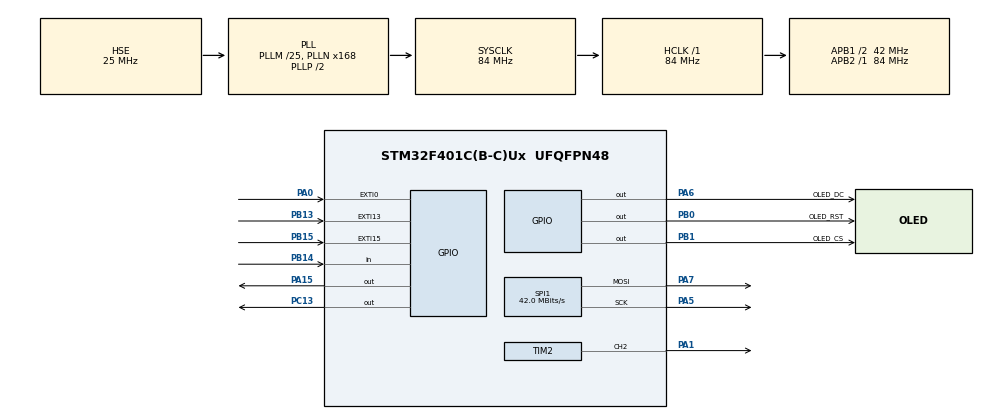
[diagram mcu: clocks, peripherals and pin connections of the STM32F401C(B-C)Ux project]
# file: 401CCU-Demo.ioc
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FREERTOS.Mutexes01=myMutex01,Dynamic,NULL
FREERTOS.Tasks01=MainTask,0,128,StartMainTask,Default,NULL,Dynamic,NULL,NULL
FREERTOS.configENABLE_FPU=1
FREERTOS.configUSE_COUNTING_SEMAPHORES=1
FREERTOS.configUSE_RECURSIVE_MUTEXES=1
Mcu.Family=STM32F4
Mcu.Name=STM32F401C(B-C)Ux
Mcu.Package=UFQFPN48
NVIC.EXTI0_IRQn=true\:5\:0\:false\:false\:true\:true\:true\:true
NVIC.EXTI15_10_IRQn=true\:5\:0\:false\:false\:true\:true\:true\:true
NVIC.PriorityGroup=NVIC_PRIORITYGROUP_4
NVIC.TIM1_UP_TIM10_IRQn=true\:15\:0\:false\:false\:true\:false\:false\:true
NVIC.TIM2_IRQn=true\:5\:0\:false\:false\:true\:true\:true\:true
NVIC.TimeBase=TIM1_UP_TIM10_IRQn
NVIC.TimeBaseIP=TIM1
PA0-WKUP.GPIO_PuPd=GPIO_PULLUP
PA0-WKUP.Signal=GPXTI0
PA1.Signal=S_TIM2_CH2
PA13.Mode=Serial_Wire
PA13.Signal=SYS_JTMS-SWDIO
PA14.Mode=Serial_Wire
PA14.Signal=SYS_JTCK-SWCLK
PA15.Signal=GPIO_Output
PA5.Mode=TX_Only_Simplex_Unidirect_Master
PA5.Signal=SPI1_SCK
PA6.GPIO_Label=OLED_DC
PA6.GPIO_Speed=GPIO_SPEED_FREQ_VERY_HIGH
PA6.Signal=GPIO_Output
PA7.Mode=TX_Only_Simplex_Unidirect_Master
PA7.Signal=SPI1_MOSI
PB0.GPIO_Label=OLED_RST
PB0.GPIO_Speed=GPIO_SPEED_FREQ_VERY_HIGH
PB0.PinState=GPIO_PIN_SET
PB0.Signal=GPIO_Output
PB1.GPIO_Label=OLED_CS
PB1.GPIO_Speed=GPIO_SPEED_FREQ_VERY_HIGH
PB1.Signal=GPIO_Output
PB13.GPIO_ModeDefaultEXTI=GPIO_MODE_IT_RISING
PB13.GPIO_PuPd=GPIO_PULLDOWN
PB13.Signal=GPXTI13
PB14.Signal=GPIO_Input
PB15.GPIO_ModeDefaultEXTI=GPIO_MODE_IT_FALLING
PB15.GPIO_PuPd=GPIO_PULLDOWN
PB15.Signal=GPXTI15
PC13-ANTI_TAMP.Signal=GPIO_Output
PC14-OSC32_IN.Mode=LSE-External-Oscillator
PC14-OSC32_IN.Signal=RCC_OSC32_IN
PC15-OSC32_OUT.Mode=LSE-External-Oscillator
PC15-OSC32_OUT.Signal=RCC_OSC32_OUT
PH0\ -\ OSC_IN.Mode=HSE-External-Oscillator
PH0\ -\ OSC_IN.Signal=RCC_OSC_IN
PH1\ -\ OSC_OUT.Mode=HSE-External-Oscillator
PH1\ -\ OSC_OUT.Signal=RCC_OSC_OUT
ProjectManager.HeapSize=0x200
ProjectManager.StackSize=0x400
ProjectManager.TargetToolchain=Makefile
RCC.48MHZClocksFreq_Value=42000000
RCC.AHBFreq_Value=84000000
RCC.APB1CLKDivider=RCC_HCLK_DIV2
RCC.APB1Freq_Value=42000000
RCC.APB1TimFreq_Value=84000000
RCC.APB2Freq_Value=84000000
RCC.APB2TimFreq_Value=84000000
RCC.CortexFreq_Value=84000000
RCC.HCLKFreq_Value=84000000
RCC.HSE_VALUE=25000000
RCC.HSI_VALUE=16000000
RCC.PLLM=25
RCC.PLLN=168
RCC.PLLSourceVirtual=RCC_PLLSOURCE_HSE
RCC.RCC_RTC_Clock_Source=RCC_RTCCLKSOURCE_LSE
RCC.SYSCLKFreq_VALUE=84000000
RCC.SYSCLKSource=RCC_SYSCLKSOURCE_PLLCLK
RCC.VCOOutputFreq_Value=168000000
SH.S_TIM2_CH2.0=TIM2_CH2,PWM Generation2 CH2
SPI1.CalculateBaudRate=42.0 MBits/s
SPI1.Direction=SPI_DIRECTION_2LINES
SPI1.Mode=SPI_MODE_MASTER
SPI1.VirtualType=VM_MASTER
TIM2.AutoReloadPreload=TIM_AUTORELOAD_PRELOAD_ENABLE
TIM2.Channel-PWM\ Generation2\ CH2=TIM_CHANNEL_2
TIM2.Period=999
TIM2.Prescaler=83
TIM2.TIM_MasterSlaveMode=TIM_MASTERSLAVEMODE_DISABLE
VP_FREERTOS_VS_CMSIS_V1.Mode=CMSIS_V1
VP_RTC_VS_RTC_Activate.Mode=RTC_Enabled
VP_SYS_VS_tim1.Mode=TIM1
VP_TIM2_VS_ClockSourceINT.Mode=Internal
board=custom

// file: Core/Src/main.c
/* USER CODE BEGIN Header */
/**
  ******************************************************************************
  * @file           : main.c
  * @brief          : Main program body
  ******************************************************************************
  * @attention
  *
  * <h2><center>&copy; Copyright (c) 2021 STMicroelectronics.
  * All rights reserved.</center></h2>
  *
  * This software component is licensed by ST under BSD 3-Clause license,
  * the "License"; You may not use this file except in compliance with the
  * License. You may obtain a copy of the License at:
  *                        opensource.org/licenses/BSD-3-Clause
  *
  ******************************************************************************
  */
/* USER CODE END Header */
#include "main.h"
#include "cmsis_os.h"

/* USER CODE BEGIN Includes */
#include "mysetp.h"
/* USER CODE END Includes */

RTC_HandleTypeDef hrtc;

SPI_HandleTypeDef hspi1;

TIM_HandleTypeDef htim2;

osThreadId MainTaskHandle;
osMutexId myMutex01Handle;

void SystemClock_Config(void);
static void MX_GPIO_Init(void);
static void MX_SPI1_Init(void);
static void MX_TIM2_Init(void);
static void MX_RTC_Init(void);
void StartMainTask(void const * argument);

int main(void)
{

  /* MCU Configuration--------------------------------------------------------*/

  /* Reset of all peripherals, Initializes the Flash interface and the Systick. */
  HAL_Init();

  /* Configure the system clock */
  SystemClock_Config();

  /* Initialize all configured peripherals */
  MX_GPIO_Init();
  MX_SPI1_Init();
  MX_TIM2_Init();
  MX_RTC_Init();
  /* USER CODE BEGIN 2 */
  HAL_TIM_Base_Start(&htim2);
  HAL_TIM_PWM_Start(&htim2,TIM_CHANNEL_2);
  /* USER CODE END 2 */

  /* Create the mutex(es) */
  /* definition and creation of myMutex01 */
  osMutexDef(myMutex01);
  myMutex01Handle = osMutexCreate(osMutex(myMutex01));

  /* Create the thread(s) */
  /* definition and creation of MainTask */
  osThreadDef(MainTask, StartMainTask, osPriorityNormal, 0, 128);
  MainTaskHandle = osThreadCreate(osThread(MainTask), NULL);

  /* Start scheduler */
  osKernelStart();

  /* We should never get here as control is now taken by the scheduler */
  /* Infinite loop */
  while (1)
  {

  }
}

void SystemClock_Config(void)
{
  RCC_OscInitTypeDef RCC_OscInitStruct = {0};
  RCC_ClkInitTypeDef RCC_ClkInitStruct = {0};

  /** Configure the main internal regulator output voltage
  */
  __HAL_RCC_PWR_CLK_ENABLE();
  __HAL_PWR_VOLTAGESCALING_CONFIG(PWR_REGULATOR_VOLTAGE_SCALE2);
  /** Initializes the RCC Oscillators according to the specified parameters
  * in the RCC_OscInitTypeDef structure.
  */
  RCC_OscInitStruct.OscillatorType = RCC_OSCILLATORTYPE_HSE|RCC_OSCILLATORTYPE_LSE;
  RCC_OscInitStruct.HSEState = RCC_HSE_ON;
  RCC_OscInitStruct.LSEState = RCC_LSE_ON;
  RCC_OscInitStruct.PLL.PLLState = RCC_PLL_ON;
  RCC_OscInitStruct.PLL.PLLSource = RCC_PLLSOURCE_HSE;
  RCC_OscInitStruct.PLL.PLLM = 25;
  RCC_OscInitStruct.PLL.PLLN = 168;
  RCC_OscInitStruct.PLL.PLLP = RCC_PLLP_DIV2;
  RCC_OscInitStruct.PLL.PLLQ = 4;
  if (HAL_RCC_OscConfig(&RCC_OscInitStruct) != HAL_OK)
  {
    Error_Handler();
  }
  /** Initializes the CPU, AHB and APB buses clocks
  */
  RCC_ClkInitStruct.ClockType = RCC_CLOCKTYPE_HCLK|RCC_CLOCKTYPE_SYSCLK
                              |RCC_CLOCKTYPE_PCLK1|RCC_CLOCKTYPE_PCLK2;
  RCC_ClkInitStruct.SYSCLKSource = RCC_SYSCLKSOURCE_PLLCLK;
  RCC_ClkInitStruct.AHBCLKDivider = RCC_SYSCLK_DIV1;
  RCC_ClkInitStruct.APB1CLKDivider = RCC_HCLK_DIV2;
  RCC_ClkInitStruct.APB2CLKDivider = RCC_HCLK_DIV1;

  if (HAL_RCC_ClockConfig(&RCC_ClkInitStruct, FLASH_LATENCY_2) != HAL_OK)
  {
    Error_Handler();
  }
}

static void MX_RTC_Init(void)
{

  /** Initialize RTC Only
  */
  hrtc.Instance = RTC;
  hrtc.Init.HourFormat = RTC_HOURFORMAT_24;
  hrtc.Init.AsynchPrediv = 127;
  hrtc.Init.SynchPrediv = 255;
  hrtc.Init.OutPut = RTC_OUTPUT_DISABLE;
  hrtc.Init.OutPutPolarity = RTC_OUTPUT_POLARITY_HIGH;
  hrtc.Init.OutPutType = RTC_OUTPUT_TYPE_OPENDRAIN;
  if (HAL_RTC_Init(&hrtc) != HAL_OK)
  {
    Error_Handler();
  }

}

static void MX_SPI1_Init(void)
{

  /* SPI1 parameter configuration*/
  hspi1.Instance = SPI1;
  hspi1.Init.Mode = SPI_MODE_MASTER;
  hspi1.Init.Direction = SPI_DIRECTION_2LINES;
  hspi1.Init.DataSize = SPI_DATASIZE_8BIT;
  hspi1.Init.CLKPolarity = SPI_POLARITY_LOW;
  hspi1.Init.CLKPhase = SPI_PHASE_1EDGE;
  hspi1.Init.NSS = SPI_NSS_SOFT;
  hspi1.Init.BaudRatePrescaler = SPI_BAUDRATEPRESCALER_2;
  hspi1.Init.FirstBit = SPI_FIRSTBIT_MSB;
  hspi1.Init.TIMode = SPI_TIMODE_DISABLE;
  hspi1.Init.CRCCalculation = SPI_CRCCALCULATION_DISABLE;
  hspi1.Init.CRCPolynomial = 10;
  if (HAL_SPI_Init(&hspi1) != HAL_OK)
  {
    Error_Handler();
  }

}

static void MX_TIM2_Init(void)
{

  TIM_ClockConfigTypeDef sClockSourceConfig = {0};
  TIM_MasterConfigTypeDef sMasterConfig = {0};
  TIM_OC_InitTypeDef sConfigOC = {0};

  htim2.Instance = TIM2;
  htim2.Init.Prescaler = 83;
  htim2.Init.CounterMode = TIM_COUNTERMODE_UP;
  htim2.Init.Period = 999;
  htim2.Init.ClockDivision = TIM_CLOCKDIVISION_DIV1;
  htim2.Init.AutoReloadPreload = TIM_AUTORELOAD_PRELOAD_ENABLE;
  if (HAL_TIM_Base_Init(&htim2) != HAL_OK)
  {
    Error_Handler();
  }
  sClockSourceConfig.ClockSource = TIM_CLOCKSOURCE_INTERNAL;
  if (HAL_TIM_ConfigClockSource(&htim2, &sClockSourceConfig) != HAL_OK)
  {
    Error_Handler();
  }
  if (HAL_TIM_PWM_Init(&htim2) != HAL_OK)
  {
    Error_Handler();
  }
  sMasterConfig.MasterOutputTrigger = TIM_TRGO_RESET;
  sMasterConfig.MasterSlaveMode = TIM_MASTERSLAVEMODE_DISABLE;
  if (HAL_TIMEx_MasterConfigSynchronization(&htim2, &sMasterConfig) != HAL_OK)
  {
    Error_Handler();
  }
  sConfigOC.OCMode = TIM_OCMODE_PWM1;
  sConfigOC.Pulse = 0;
  sConfigOC.OCPolarity = TIM_OCPOLARITY_HIGH;
  sConfigOC.OCFastMode = TIM_OCFAST_DISABLE;
  if (HAL_TIM_PWM_ConfigChannel(&htim2, &sConfigOC, TIM_CHANNEL_2) != HAL_OK)
  {
    Error_Handler();
  }
  HAL_TIM_MspPostInit(&htim2);

}

static void MX_GPIO_Init(void)
{
  GPIO_InitTypeDef GPIO_InitStruct = {0};

  /* GPIO Ports Clock Enable */
  __HAL_RCC_GPIOC_CLK_ENABLE();
  __HAL_RCC_GPIOH_CLK_ENABLE();
  __HAL_RCC_GPIOA_CLK_ENABLE();
  __HAL_RCC_GPIOB_CLK_ENABLE();

  /*Configure GPIO pin Output Level */
  HAL_GPIO_WritePin(GPIOC, GPIO_PIN_13, GPIO_PIN_RESET);

  /*Configure GPIO pin Output Level */
  HAL_GPIO_WritePin(GPIOA, OLED_DC_Pin|GPIO_PIN_15, GPIO_PIN_RESET);

  /*Configure GPIO pin Output Level */
  HAL_GPIO_WritePin(OLED_RST_GPIO_Port, OLED_RST_Pin, GPIO_PIN_SET);

  /*Configure GPIO pin Output Level */
  HAL_GPIO_WritePin(OLED_CS_GPIO_Port, OLED_CS_Pin, GPIO_PIN_RESET);

  /*Configure GPIO pin : PC13 */
  GPIO_InitStruct.Pin = GPIO_PIN_13;
  GPIO_InitStruct.Mode = GPIO_MODE_OUTPUT_PP;
  GPIO_InitStruct.Pull = GPIO_NOPULL;
  GPIO_InitStruct.Speed = GPIO_SPEED_FREQ_LOW;
  HAL_GPIO_Init(GPIOC, &GPIO_InitStruct);

  /*Configure GPIO pin : PA0 */
  GPIO_InitStruct.Pin = GPIO_PIN_0;
  GPIO_InitStruct.Mode = GPIO_MODE_IT_RISING;
  GPIO_InitStruct.Pull = GPIO_PULLUP;
  HAL_GPIO_Init(GPIOA, &GPIO_InitStruct);

  /*Configure GPIO pin : OLED_DC_Pin */
  GPIO_InitStruct.Pin = OLED_DC_Pin;
  GPIO_InitStruct.Mode = GPIO_MODE_OUTPUT_PP;
  GPIO_InitStruct.Pull = GPIO_NOPULL;
  GPIO_InitStruct.Speed = GPIO_SPEED_FREQ_VERY_HIGH;
  HAL_GPIO_Init(OLED_DC_GPIO_Port, &GPIO_InitStruct);

  /*Configure GPIO pins : OLED_RST_Pin OLED_CS_Pin */
  GPIO_InitStruct.Pin = OLED_RST_Pin|OLED_CS_Pin;
  GPIO_InitStruct.Mode = GPIO_MODE_OUTPUT_PP;
  GPIO_InitStruct.Pull = GPIO_NOPULL;
  GPIO_InitStruct.Speed = GPIO_SPEED_FREQ_VERY_HIGH;
  HAL_GPIO_Init(GPIOB, &GPIO_InitStruct);

  /*Configure GPIO pin : PB13 */
  GPIO_InitStruct.Pin = GPIO_PIN_13;
  GPIO_InitStruct.Mode = GPIO_MODE_IT_RISING;
  GPIO_InitStruct.Pull = GPIO_PULLDOWN;
  HAL_GPIO_Init(GPIOB, &GPIO_InitStruct);

  /*Configure GPIO pin : PB14 */
  GPIO_InitStruct.Pin = GPIO_PIN_14;
  GPIO_InitStruct.Mode = GPIO_MODE_INPUT;
  GPIO_InitStruct.Pull = GPIO_NOPULL;
  HAL_GPIO_Init(GPIOB, &GPIO_InitStruct);

  /*Configure GPIO pin : PB15 */
  GPIO_InitStruct.Pin = GPIO_PIN_15;
  GPIO_InitStruct.Mode = GPIO_MODE_IT_FALLING;
  GPIO_InitStruct.Pull = GPIO_PULLDOWN;
  HAL_GPIO_Init(GPIOB, &GPIO_InitStruct);

  /*Configure GPIO pin : PA15 */
  GPIO_InitStruct.Pin = GPIO_PIN_15;
  GPIO_InitStruct.Mode = GPIO_MODE_OUTPUT_PP;
  GPIO_InitStruct.Pull = GPIO_NOPULL;
  GPIO_InitStruct.Speed = GPIO_SPEED_FREQ_LOW;
  HAL_GPIO_Init(GPIOA, &GPIO_InitStruct);

  /* EXTI interrupt init*/
  HAL_NVIC_SetPriority(EXTI0_IRQn, 5, 0);
  HAL_NVIC_EnableIRQ(EXTI0_IRQn);

  HAL_NVIC_SetPriority(EXTI15_10_IRQn, 5, 0);
  HAL_NVIC_EnableIRQ(EXTI15_10_IRQn);

}

void StartMainTask(void const * argument)
{
  /* USER CODE BEGIN 5 */
  /* Infinite loop */
  for(;;)
  {

    osDelay(1);
    setp();
  }
  /* USER CODE END 5 */
}

void HAL_TIM_PeriodElapsedCallback(TIM_HandleTypeDef *htim)
{
  if (htim->Instance == TIM1) {
    HAL_IncTick();
  }
}

void Error_Handler(void)
{
  __disable_irq();
  while (1)
  {
  }
}

/************************ (C) COPYRIGHT STMicroelectronics *****END OF FILE****/
